# soc register map
Vendor: litex
Registers are 32-bit, read-write, reset 0x0 unless marked. A register's access mark holds for its fields unless they carry their own. Offsets are from the block's base; [hi:lo] are bit positions.

## DUT
Base 0xF0003000
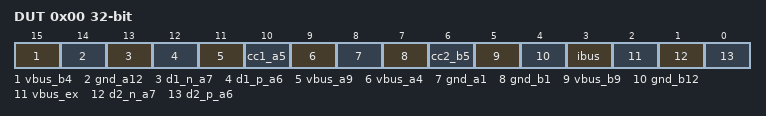
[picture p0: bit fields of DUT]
0x00 DUT — Bits that drive the DUT signal switches
  [15] vbus_b4 — Set to connect vbus_b4 to test source
  [14] gnd_a12 — Set to connect gnd_a12 to test source
  [13] d1_n_a7 — Set to connect d1_n_a7 to test source
  [12] d1_p_a6 — Set to connect d1_p_a6 to test source
  [11] vbus_a9 — Set to connect vbus_a9 to test source
  [10] cc1_a5 — Set to connect cc1_a5 to test source
  [9] vbus_a4 — Set to connect vbus_a4 to test source
  [8] gnd_a1 — Set to connect gnd_a1 to test source
  [7] gnd_b1 — Set to connect gnd_b1 to test source
  [6] cc2_b5 — Set to connect cc2_b5 to test source
  [5] vbus_b9 — Set to connect vbus_b9 to test source
  [4] gnd_b12 — Set to connect gnd_b12 to test source
  [3] ibus — Set to connect ibus to test source
  [2] vbus_ex — Set to connect vbus_ex to test source
  [1] d2_n_a7 — Set to connect d2_n_a7 to test source
  [0] d2_p_a6 — Set to connect d2_p_a6 to test source
0x04 RUN — Pulled low when the `run` switch is depressed
  [0] run

## ADC
Base 0xF0003800
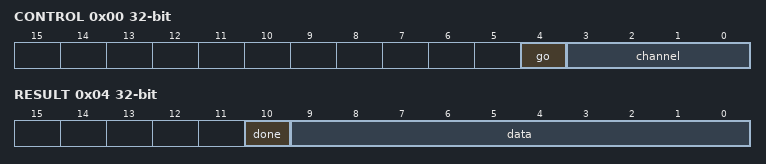
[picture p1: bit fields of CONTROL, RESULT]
0x00 CONTROL
  [4] go — Start the conversion
  [3:0] channel — Select the ADC channel
0x04 RESULT
  [10] done — Conversion is done. Cleared on read.
  [9:0] data — Result of last conversion

## SBLED
Base 0xF0005000
0x00 DAT — This is the value for the ``SB_LEDDA_IP.DAT`` register. It is directly written into the ``SB_LEDDA_IP`` hardware block, so you should refer to http://www.latticesemi.com/view_document?document_id=50668. The contents of this register are written to the address specified in ``ADDR`` immediately upon writing this register.
  [7:0] dat
0x04 ADDR — This register is directly connected to ``SB_LEDDA_IP.ADDR``. This register controls the address that is updated whenever ``DAT`` is written. Writing to this register has no immediate effect -- data isn't written until the ``DAT`` register is written.
  [3:0] addr
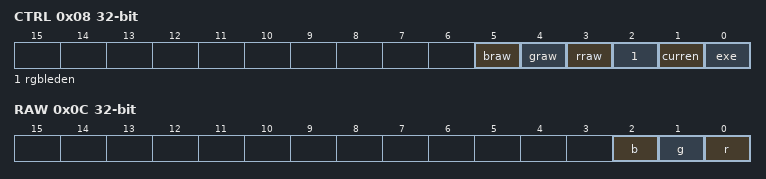
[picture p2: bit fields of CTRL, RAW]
0x08 CTRL — Control logic for the RGB LED and LEDDA hardware PWM LED block.
  [5] braw — Set this to ``1`` to enable raw control of the blue LED via the ``RAW.B`` register.
  [4] graw — Set this to ``1`` to enable raw control of the green LED via the ``RAW.G`` register.
  [3] rraw — Set this to ``1`` to enable raw control of the red LED via the ``RAW.R`` register.
  [2] rgbleden — Connected to ``SB_RGBA_DRV.RGBLEDEN``. Set this to ``1`` to enable the RGB PWM control logic.
  [1] curren — Connected to ``SB_RGBA_DRV.CURREN``. Set this to ``1`` to enable the current source.
  [0] exe — Connected to ``SB_LEDDA_IP.LEDDEXE``. Set this to ``1`` to enable the fading pattern.
0x0C RAW — Normally the hardware ``SB_LEDDA_IP`` block controls the brightness of the LED, creating a gentle fading pattern. However, by setting the appropriate bit in ``CTRL``, it is possible to manually control the three individual LEDs.
  [2] b — Raw value for the blue LED when ``CTRL.BRAW`` is ``1``.
  [1] g — Raw value for the green LED when ``CTRL.GRAW`` is ``1``.
  [0] r — Raw value for the red LED when ``CTRL.RRAW`` is ``1``.

## CTRL
Base 0xF0005800
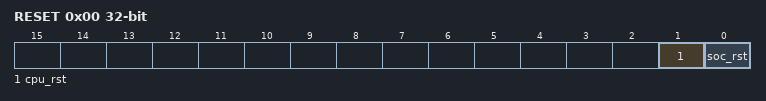
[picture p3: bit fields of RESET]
0x00 RESET
  [1] cpu_rst — Write `1` to this register to reset the CPU(s) of the SoC (Hold Reset)
  [0] soc_rst — Write `1` to this register to reset the full SoC (Pulse Reset)
0x04 SCRATCH reset 0x12345678 — Use this register as a scratch space to verify that software read/write accesses to the Wishbone/CSR bus are working correctly. The initial reset value of 0x1234578 can be used to verify endianness.
0x08 BUS_ERRORS — Total number of Wishbone bus errors (timeouts) since start.

## IDENTIFIER_MEM
Base 0xF0006000
0x00 IDENTIFIER_MEM — 8 x 12-bit memory
  [7:0] identifier_mem

## TIMER0
Base 0xF0006800
0x00 LOAD — Load value when Timer is (re-)enabled. In One-Shot mode, the value written to this register specifies the Timer's duration in clock cycles.
0x04 RELOAD — Reload value when Timer reaches ``0``. In Periodic mode, the value written to this register specify the Timer's period in clock cycles.
0x08 EN — Enable flag of the Timer. Set this flag to ``1`` to enable/start the Timer. Set to ``0`` to disable the Timer.
  [0] en
0x0C UPDATE_VALUE — Update trigger for the current countdown value. A write to this register latches the current countdown value to ``value`` register.
  [0] update_value
0x10 VALUE — Latched countdown value. This value is updated by writing to ``update_value``.
0x14 EV_STATUS — This register contains the current raw level of the zero event trigger. Writes to this register have no effect.
  [0] zero — Level of the ``zero`` event
0x18 EV_PENDING — When a zero event occurs, the corresponding bit will be set in this register. To clear the Event, set the corresponding bit in this register.
  [0] zero — `1` if a `zero` event occurred. This Event is triggered on a **falling** edge.
0x1C EV_ENABLE — This register enables the corresponding zero events. Write a ``0`` to this register to disable individual events.
  [0] zero — Write a ``1`` to enable the ``zero`` Event
